# VIP1_top_level register map
Vendor: Texas Instruments
Peripheral module from a debugger description file (folder DRA74xP_75xP_76xP_77xP).
Registers are 32-bit, access per field, reset 0x0 unless marked. A register's access mark holds for its fields unless they carry their own. Offsets are as the file gives them; lines under a group give offsets from that group; [hi:lo] are bit positions; {n}, {i} and the like mark numbered series; 'fields as' and 'values as' point back to an identical list; <NAME> marks a mode.

## VIP1_top_level
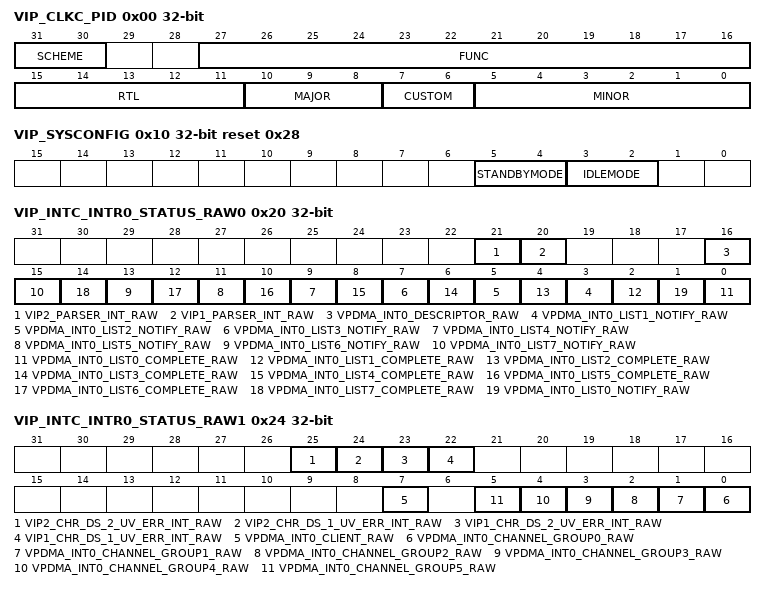
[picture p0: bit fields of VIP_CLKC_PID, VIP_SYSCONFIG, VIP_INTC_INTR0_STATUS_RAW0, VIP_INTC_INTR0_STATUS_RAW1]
0x00 VIP_CLKC_PID ro — This register follows the format described in PDR3.5
  [31:30] SCHEME — The scheme of the register used. This indicates the PDR3.5 Method
  [27:16] FUNC — The function of the module being used
  [15:11] RTL — RTL Release Version The PDR release number of this IP
  [10:8] MAJOR — ajor Release Number
  [7:6] CUSTOM — Custom IP
  [5:0] MINOR — inor Release Number
0x10 VIP_SYSCONFIG reset 0x28
  [5:4] STANDBYMODE rw — Configuration of the local initiator state management mode. By definition, initiator may generate read/write transaction as long as it is out of STANDBY state 0x0: Force-standby mode: local initiator is unconditionally placed in standby state. Backup mode, for debug only 0x1: No-standby mode: local initiator is unconditionally placed out of standby state. Backup mode, for debug only 0x2: Same behavior as bit-field value of 0x1. 0x3: Reserved
  [3:2] IDLEMODE rw — Configuration of the local target state management mode. By definition, target can handle read/write transaction as long as it is out of IDLE state 0x0 : Force-idle mode: local target's idle state follows (acknowledges) the system's idle requests unconditionally, i.e. regardless of the IP module's internal requirements. Backup mode, for debug only 0x1 : No-idle mode: local target never enters idle state. Backup mode, for debug only 0x2 : Smart-idle mode: local target's idle state eventually follows (acknowledges) the system's idle requests, depending on the IP module's internal requirements. IP module shall not generate (IRQ- or DMA-request-related) wakeup events 0x3 : Smart-idle wakeup-capable mode: local target's idle state eventually follows (acknowledges) the system's idle requests, depending on the IP module's internal requirements. IP module may generate (IRQ- or DMA-request-related) wakeup events when in idle state. Mode is only relevant if the appropriate IP module 'swakeup' output(s) is (are) implemented
0x20 VIP_INTC_INTR0_STATUS_RAW0 — INTC INTR0 Interrupt Status Raw/Set Register 0. This register contains the raw interrupt status as defined in HL0.8
  [21] VIP2_PARSER_INT_RAW rw — VIP2 Parser Interrupt Status Read indicates raw status 0 = inactive 1 = active Writing 1 will set status Writing 0 has no effect
  [20] VIP1_PARSER_INT_RAW rw — VIP1 Parser Interrupt Status Read indicates raw status 0 = inactive 1 = active Writing 1 will set status Writing 0 has no effect
  [16] VPDMA_INT0_DESCRIPTOR_RAW rw — VPDMA INT0 Descriptor Status Read indicates raw status 0 = inactive 1 = active Writing 1 will set status Writing 0 has no effect
  [2n+1] VPDMA_INT0_LIST{n}_NOTIFY_RAW rw (n=1..7) — VPDMA INT0 List{n} Complete Status Read indicates raw status 0 = inactive 1 = active Writing 1 will set status Writing 0 has no effect
  [2n] VPDMA_INT0_LIST{n}_COMPLETE_RAW rw (n=0..7) — VPDMA INT0 List{n} Complete Status Read indicates raw status 0 = inactive 1 = active Writing 1 will set status Writing 0 has no effect
  [1] VPDMA_INT0_LIST0_NOTIFY_RAW rw — VPDMA INT0 List0 Notify Status Read indicates raw status 0 = inactive 1 = active Writing 1 will set status Writing 0 has no effect
0x24 VIP_INTC_INTR0_STATUS_RAW1 — INTC INTR0 Interrupt Status Raw/Set Register 1. This register contains the raw interrupt status as defined in HL0.8
  [25] VIP2_CHR_DS_2_UV_ERR_INT_RAW rw — VIP2 Chroma Downsampler 2 UV Error Interrupt Status Read indicates raw status 0 = inactive 1 = active Writing 1 will set status Writing 0 has no effect
  [24] VIP2_CHR_DS_1_UV_ERR_INT_RAW rw — VIP2 Chroma Downsampler 1 UV Error Interrupt Status Read indicates raw status 0 = inactive 1 = active Writing 1 will set status Writing 0 has no effect
  [23] VIP1_CHR_DS_2_UV_ERR_INT_RAW rw — VIP1 Chroma Downsampler 2 UV Error Interrupt Status Read indicates raw status 0 = inactive 1 = active Writing 1 will set status Writing 0 has no effect
  [22] VIP1_CHR_DS_1_UV_ERR_INT_RAW rw — VIP1 Chroma Downsampler 1 UV Error Interrupt Status Read indicates raw status 0 = inactive 1 = active Writing 1 will set status Writing 0 has no effect
  [7] VPDMA_INT0_CLIENT_RAW rw — VPDMA INT0 Client Status Read indicates raw status 0 = inactive 1 = active Writing 1 will set status Writing 0 has no effect
  [n] VPDMA_INT0_CHANNEL_GROUP{n}_RAW rw (n=0..5) — VPDMA INT0 Channel Group{n} Status Read indicates raw status 0 = inactive 1 = active Writing 1 will set status Writing 0 has no effect
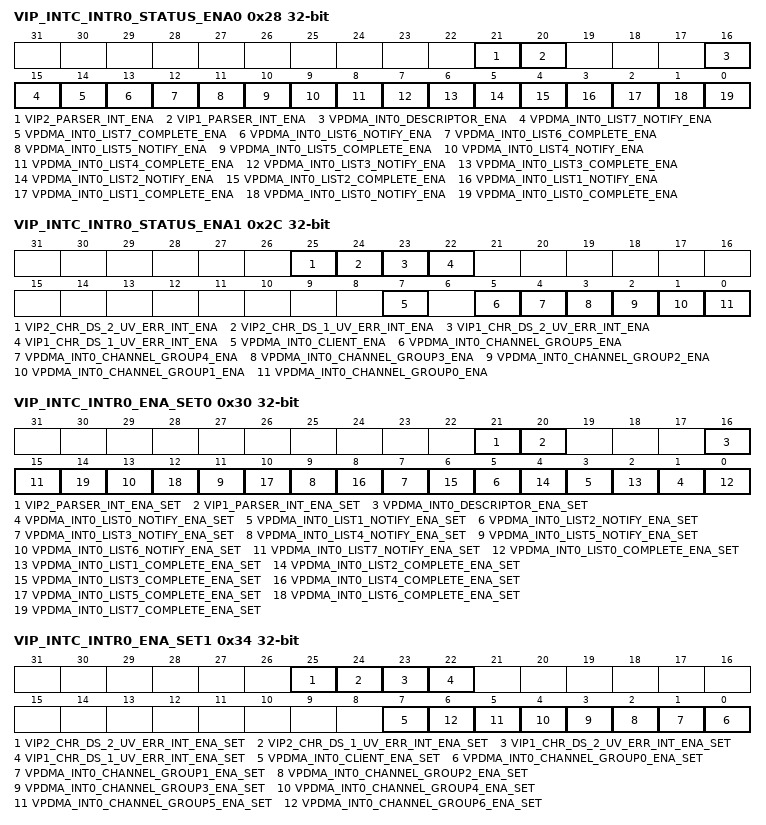
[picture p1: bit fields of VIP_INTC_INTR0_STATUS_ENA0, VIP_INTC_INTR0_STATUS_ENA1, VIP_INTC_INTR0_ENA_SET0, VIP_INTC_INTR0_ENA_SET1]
0x28 VIP_INTC_INTR0_STATUS_ENA0 — INTC INTR0 Interrupt Status Enabled/Clear Register 0. This register contains the enabled interrupt status as defined in HL0.8
  [21] VIP2_PARSER_INT_ENA rw — VIP2 Parser Enabled Interrupt Status Read indicates enabled status 0 = inactive 1 = active Writing 1 will clear interrupt Writing 0 has no effect
  [20] VIP1_PARSER_INT_ENA rw — VIP1 Parser Enabled Interrupt Status Read indicates enabled status 0 = inactive 1 = active Writing 1 will clear interrupt Writing 0 has no effect
  [16] VPDMA_INT0_DESCRIPTOR_ENA rw — VPDMA INT0 Descriptor Enabled Status Read indicates interrupt enable 0 = disabled 1 = enabled Writing 1 will set interrupt enabled Writing 0 has no effect
  [15] VPDMA_INT0_LIST7_NOTIFY_ENA rw — VPDMA INT0 List7 Notify Enabled Status Read indicates interrupt enable 0 = disabled 1 = enabled Writing 1 will set interrupt enabled Writing 0 has no effect
  [14] VPDMA_INT0_LIST7_COMPLETE_ENA rw — VPDMA INT0 List7 Complete Enabled Status Read indicates interrupt enable 0 = disabled 1 = enabled Writing 1 will set interrupt enabled Writing 0 has no effect
  [13] VPDMA_INT0_LIST6_NOTIFY_ENA rw — VPDMA INT0 List6 Notify Enabled Status Read indicates interrupt enable 0 = disabled 1 = enabled Writing 1 will set interrupt enabled Writing 0 has no effect
  [12] VPDMA_INT0_LIST6_COMPLETE_ENA rw — VPDMA INT0 List6 Complete Enabled Status Read indicates interrupt enable 0 = disabled 1 = enabled Writing 1 will set interrupt enabled Writing 0 has no effect
  [11] VPDMA_INT0_LIST5_NOTIFY_ENA rw — VPDMA INT0 List5 Notify Enabled Status Read indicates interrupt enable 0 = disabled 1 = enabled Writing 1 will set interrupt enabled Writing 0 has no effect
  [10] VPDMA_INT0_LIST5_COMPLETE_ENA rw — VPDMA INT0 List5 Complete Enabled Statust Read indicates interrupt enable 0 = disabled 1 = enabled Writing 1 will set interrupt enabled Writing 0 has no effect
  [9] VPDMA_INT0_LIST4_NOTIFY_ENA rw — VPDMA INT0 List4 Notify Enabled Statust Read indicates interrupt enable 0 = disabled 1 = enabled Writing 1 will set interrupt enabled Writing 0 has no effect
  [8] VPDMA_INT0_LIST4_COMPLETE_ENA rw — VPDMA INT0 List4 Complete Enabled Status Read indicates interrupt enable 0 = disabled 1 = enabled Writing 1 will set interrupt enabled Writing 0 has no effect
  [7] VPDMA_INT0_LIST3_NOTIFY_ENA rw — VPDMA INT0 List3 Notify Enabled Status Read indicates interrupt enable 0 = disabled 1 = enabled Writing 1 will set interrupt enabled Writing 0 has no effect
  [6] VPDMA_INT0_LIST3_COMPLETE_ENA rw — VPDMA INT0 List3 Complete Enabled Status Read indicates interrupt enable 0 = disabled 1 = enabled Writing 1 will set interrupt enabled Writing 0 has no effect
  [5] VPDMA_INT0_LIST2_NOTIFY_ENA rw — VPDMA INT0 List2 Notify Enabled Statust Read indicates interrupt enable 0 = disabled 1 = enabled Writing 1 will set interrupt enabled Writing 0 has no effect
  [4] VPDMA_INT0_LIST2_COMPLETE_ENA rw — VPDMA INT0 List2 Complete Enabled Statust Read indicates interrupt enable 0 = disabled 1 = enabled Writing 1 will set interrupt enabled Writing 0 has no effect
  [3] VPDMA_INT0_LIST1_NOTIFY_ENA rw — VPDMA INT0 List1 Notify Enabled Status Read indicates interrupt enable 0 = disabled 1 = enabled Writing 1 will set interrupt enabled Writing 0 has no effect
  [2] VPDMA_INT0_LIST1_COMPLETE_ENA rw — VPDMA INT0 List1 Complete Enabled Status Read indicates interrupt enable 0 = disabled 1 = enabled Writing 1 will set interrupt enabled Writing 0 has no effect
  [1] VPDMA_INT0_LIST0_NOTIFY_ENA rw — VPDMA INT0 List0 Notify Enabled Status Read indicates interrupt enable 0 = disabled 1 = enabled Writing 1 will set interrupt enabled Writing 0 has no effect
  [0] VPDMA_INT0_LIST0_COMPLETE_ENA rw — VPDMA INT0 List0 Complete Enabled Status Read indicates interrupt enable 0 = disabled 1 = enabled Writing 1 will set interrupt enabled Writing 0 has no effect
0x2C VIP_INTC_INTR0_STATUS_ENA1 — INTC INTR0 Interrupt Status Enabled/Clear Register 1. This register contains the enabled interrupt status as defined in HL0.8
  [25] VIP2_CHR_DS_2_UV_ERR_INT_ENA rw — VIP2 Chroma Downsampler 2 UV Error Enabled Interrupt Status Read indicates enabled status 0 = inactive 1 = active Writing 1 will clear interrupt Writing 0 has no effect
  [24] VIP2_CHR_DS_1_UV_ERR_INT_ENA rw — VIP2 Chroma Downsampler 1 UV Error Enabled Interrupt Status Read indicates enabled status 0 = inactive 1 = active Writing 1 will clear interrupt Writing 0 has no effect
  [23] VIP1_CHR_DS_2_UV_ERR_INT_ENA rw — VIP1 Chroma Downsampler 2 UV Error Enabled Interrupt Status Read indicates enabled status 0 = inactive 1 = active Writing 1 will clear interrupt Writing 0 has no effect
  [22] VIP1_CHR_DS_1_UV_ERR_INT_ENA rw — VIP1 Chroma Downsampler 1 UV Error Enabled Interrupt Status Read indicates enabled status 0 = inactive 1 = active Writing 1 will clear interrupt Writing 0 has no effect
  [7] VPDMA_INT0_CLIENT_ENA rw — VPDMA INT0 Client Enabled Status Read indicates raw status 0 = inactive 1 = active Writing 1 will set status Writing 0 has no effect
  [5] VPDMA_INT0_CHANNEL_GROUP5_ENA rw — VPDMA INT0 Channel Group5 Enabled Status Read indicates raw status 0 = inactive 1 = active Writing 1 will set status Writing 0 has no effect
  [4] VPDMA_INT0_CHANNEL_GROUP4_ENA rw — VPDMA INT0 Channel Group4 Enabled Status Read indicates raw status 0 = inactive 1 = active Writing 1 will set status Writing 0 has no effect
  [3] VPDMA_INT0_CHANNEL_GROUP3_ENA rw — VPDMA INT0 Channel Group3 Enabled Status Read indicates raw status 0 = inactive 1 = active Writing 1 will set status Writing 0 has no effect
  [2] VPDMA_INT0_CHANNEL_GROUP2_ENA rw — VPDMA INT0 Channel Group3 Enabled Status Read indicates raw status 0 = inactive 1 = active Writing 1 will set status Writing 0 has no effect
  [1] VPDMA_INT0_CHANNEL_GROUP1_ENA rw — VPDMA INT0 Channel Group1 Enabled Status Read indicates raw status 0 = inactive 1 = active Writing 1 will set status Writing 0 has no effect
  [0] VPDMA_INT0_CHANNEL_GROUP0_ENA rw — VPDMA INT0 Channel Group0 Enabled Status Read indicates raw status 0 = inactive 1 = active Writing 1 will set status Writing 0 has no effect
0x30 VIP_INTC_INTR0_ENA_SET0 — INTC INTR0 Interrupt Enable/Set Register 0. This register contains the interrupt enable status/set as defined in HL0.8
  [21] VIP2_PARSER_INT_ENA_SET rw — VIP2 Parser Enable/Set Read indicates interrupt enable 0 = disabled 1 = enabled Writing 1 will set interrupt enabled Writing 0 has no effect
  [20] VIP1_PARSER_INT_ENA_SET rw — VIP1 Parser Enable/Set Read indicates interrupt enable 0 = disabled 1 = enabled Writing 1 will set interrupt enabled Writing 0 has no effect
  [16] VPDMA_INT0_DESCRIPTOR_ENA_SET rw — VPDMA INT0 Descriptor Enable/Set Read indicates interrupt enable 0 = disabled 1 = enabled Writing 1 will set interrupt enabled Writing 0 has no effect
  [2n+1] VPDMA_INT0_LIST{n}_NOTIFY_ENA_SET rw (n=0..7) — VPDMA INT0 List{n} Notify Enable/Set Read indicates interrupt enable 0 = disabled 1 = enabled Writing 1 will set interrupt enabled Writing 0 has no effect
  [2n] VPDMA_INT0_LIST{n}_COMPLETE_ENA_SET rw (n=0..7) — VPDMA INT0 List{n} Complete Enable/Set Read indicates interrupt enable 0 = disabled 1 = enabled Writing 1 will set interrupt enabled Writing 0 has no effect
0x34 VIP_INTC_INTR0_ENA_SET1 — INTC INTR0 Interrupt Enable/Set Register 1. This register contains the interrupt enable status/set as defined in HL0.8
  [25] VIP2_CHR_DS_2_UV_ERR_INT_ENA_SET rw — VIP2 Chroma Downsampler 2 UV Error Enable/Set Read indicates interrupt enable 0 = disabled 1 = enabled Writing 1 will set interrupt enabled Writing 0 has no effect
  [24] VIP2_CHR_DS_1_UV_ERR_INT_ENA_SET rw — VIP2 Chroma Downsampler 1 UV Error Enable/Set Read indicates interrupt enable 0 = disabled 1 = enabled Writing 1 will set interrupt enabled Writing 0 has no effect
  [23] VIP1_CHR_DS_2_UV_ERR_INT_ENA_SET rw — VIP1 Chroma Downsampler 2 UV Error Enable/Set Read indicates interrupt enable 0 = disabled 1 = enabled Writing 1 will set interrupt enabled Writing 0 has no effect
  [22] VIP1_CHR_DS_1_UV_ERR_INT_ENA_SET rw — VIP1 Chroma Downsampler 1 UV Error Enable/Set Read indicates interrupt enable 0 = disabled 1 = enabled Writing 1 will set interrupt enabled Writing 0 has no effect
  [7] VPDMA_INT0_CLIENT_ENA_SET rw — VPDMA INT0 Client Enable/Set Read indicates interrupt enable 0 = disabled 1 = enabled Writing 1 will set interrupt enabled Writing 0 has no effect
  [n] VPDMA_INT0_CHANNEL_GROUP{n}_ENA_SET rw (n=0..6) — VPDMA INT0 Channel Group{n} Enable/Set Read indicates interrupt enable 0 = disabled 1 = enabled Writing 1 will set interrupt enabled Writing 0 has no effect
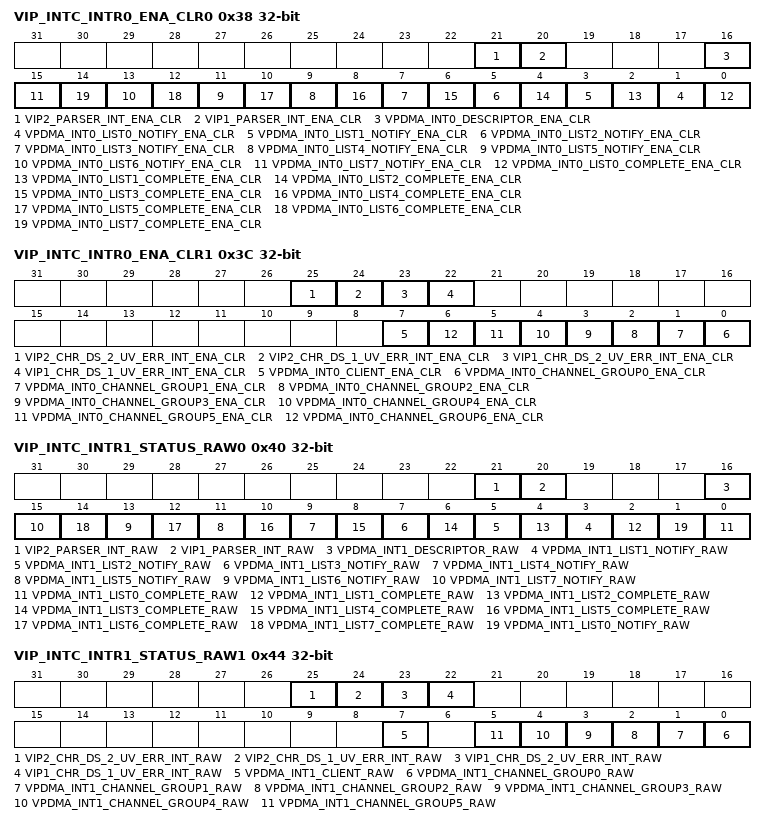
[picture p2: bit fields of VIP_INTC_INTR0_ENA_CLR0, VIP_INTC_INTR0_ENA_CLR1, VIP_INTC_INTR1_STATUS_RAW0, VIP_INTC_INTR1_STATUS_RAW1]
0x38 VIP_INTC_INTR0_ENA_CLR0 — INTC INTR0 Interrupt Enable/Clear Register 0. This register contains the interrupt enable status/clear as defined in HL0.8
  [21] VIP2_PARSER_INT_ENA_CLR rw — VIP2 Parser Enable/Clear Read indicates interrupt enable 0 = disabled 1 = enabled Writing 1 will clear interrupt enabled Writing 0 has no effect
  [20] VIP1_PARSER_INT_ENA_CLR rw — VIP1 Parser Enable/Clear Read indicates interrupt enable 0 = disabled 1 = enabled Writing 1 will clear interrupt enabled Writing 0 has no effect
  [16] VPDMA_INT0_DESCRIPTOR_ENA_CLR rw — VPDMA INT0 Descriptor Enable/Clear Read indicates interrupt enable 0 = disabled 1 = enabled Writing 1 will clear interrupt enabled Writing 0 has no effect
  [2n+1] VPDMA_INT0_LIST{n}_NOTIFY_ENA_CLR rw (n=0..7) — VPDMA INT0 List{n} Notify Enable/Clear Read indicates interrupt enable 0 = disabled 1 = enabled Writing 1 will clear interrupt enabled Writing 0 has no effect
  [2n] VPDMA_INT0_LIST{n}_COMPLETE_ENA_CLR rw (n=0..7) — VPDMA INT0 List{n} Complete Enable/Clear Read indicates interrupt enable 0 = disabled 1 = enabled Writing 1 will clear interrupt enabled Writing 0 has no effect
0x3C VIP_INTC_INTR0_ENA_CLR1 — INTC INTR0 Interrupt Enable/Clear Register 1. This register contains the interrupt enable status/clear as defined in HL0.8
  [25] VIP2_CHR_DS_2_UV_ERR_INT_ENA_CLR rw — VIP2 Chroma Downsampler 2 UV Error Enable/Clear Read indicates interrupt enable 0 = disabled 1 = enabled Writing 1 will clear interrupt enabled Writing 0 has no effect
  [24] VIP2_CHR_DS_1_UV_ERR_INT_ENA_CLR rw — VIP2 Chroma Downsampler 1 UV Error Enable/Clear Read indicates interrupt enable 0 = disabled 1 = enabled Writing 1 will clear interrupt enabled Writing 0 has no effect
  [23] VIP1_CHR_DS_2_UV_ERR_INT_ENA_CLR rw — VIP1 Chroma Downsampler 2 UV Error Enable/Clear Read indicates interrupt enable 0 = disabled 1 = enabled Writing 1 will clear interrupt enabled Writing 0 has no effect
  [22] VIP1_CHR_DS_1_UV_ERR_INT_ENA_CLR rw — VIP1 Chroma Downsampler 1 UV Error Enable/Clear Read indicates interrupt enable 0 = disabled 1 = enabled Writing 1 will clear interrupt enabled Writing 0 has no effect
  [7] VPDMA_INT0_CLIENT_ENA_CLR rw — VPDMA INT0 Client Enable/Clear Read indicates interrupt enable 0 = disabled 1 = enabled Writing 1 will clear interrupt enabled Writing 0 has no effect
  [n] VPDMA_INT0_CHANNEL_GROUP{n}_ENA_CLR rw (n=0..6) — VPDMA INT0 Channel Group{n} Enable/Clear Read indicates interrupt enable 0 = disabled 1 = enabled Writing 1 will clear interrupt enabled Writing 0 has no effect
0x40 VIP_INTC_INTR1_STATUS_RAW0 — INTC intr1 Interrupt Status Raw/Set Register 0. This register contains the raw interrupt status as defined in HL0.8
  [21] VIP2_PARSER_INT_RAW rw — VIP2 Parser Interrupt Status Read indicates raw status 0 = inactive 1 = active Writing 1 will set status Writing 0 has no effect
  [20] VIP1_PARSER_INT_RAW rw — VIP1 Parser Interrupt Status Read indicates raw status 0 = inactive 1 = active Writing 1 will set status Writing 0 has no effect
  [16] VPDMA_INT1_DESCRIPTOR_RAW rw — VPDMA INT1 Descriptor Status Read indicates raw status 0 = inactive 1 = active Writing 1 will set status Writing 0 has no effect
  [2n+1] VPDMA_INT1_LIST{n}_NOTIFY_RAW rw (n=1..7) — VPDMA INT1 List{n} Complete Status Read indicates raw status 0 = inactive 1 = active Writing 1 will set status Writing 0 has no effect
  [2n] VPDMA_INT1_LIST{n}_COMPLETE_RAW rw (n=0..7) — VPDMA INT1 List{n} Complete Status Read indicates raw status 0 = inactive 1 = active Writing 1 will set status Writing 0 has no effect
  [1] VPDMA_INT1_LIST0_NOTIFY_RAW rw — VPDMA INT1 List0 Notify Status Read indicates raw status 0 = inactive 1 = active Writing 1 will set status Writing 0 has no effect
0x44 VIP_INTC_INTR1_STATUS_RAW1 — INTC intr1 Interrupt Status Raw/Set Register 1. This register contains the raw interrupt status as defined in HL0.8
  [25] VIP2_CHR_DS_2_UV_ERR_INT_RAW rw — VIP2 Chroma Downsampler 2 UV Error Interrupt Status Read indicates raw status 0 = inactive 1 = active Writing 1 will set status Writing 0 has no effect
  [24] VIP2_CHR_DS_1_UV_ERR_INT_RAW rw — VIP2 Chroma Downsampler 1 UV Error Interrupt Status Read indicates raw status 0 = inactive 1 = active Writing 1 will set status Writing 0 has no effect
  [23] VIP1_CHR_DS_2_UV_ERR_INT_RAW rw — VIP1 Chroma Downsampler 2 UV Error Interrupt Status Read indicates raw status 0 = inactive 1 = active Writing 1 will set status Writing 0 has no effect
  [22] VIP1_CHR_DS_1_UV_ERR_INT_RAW rw — VIP1 Chroma Downsampler 1 UV Error Interrupt Status Read indicates raw status 0 = inactive 1 = active Writing 1 will set status Writing 0 has no effect
  [7] VPDMA_INT1_CLIENT_RAW rw — VPDMA INT1 Client Status Read indicates raw status 0 = inactive 1 = active Writing 1 will set status Writing 0 has no effect
  [n] VPDMA_INT1_CHANNEL_GROUP{n}_RAW rw (n=0..5) — VPDMA INT1 Channel Group{n} Status Read indicates raw status 0 = inactive 1 = active Writing 1 will set status Writing 0 has no effect
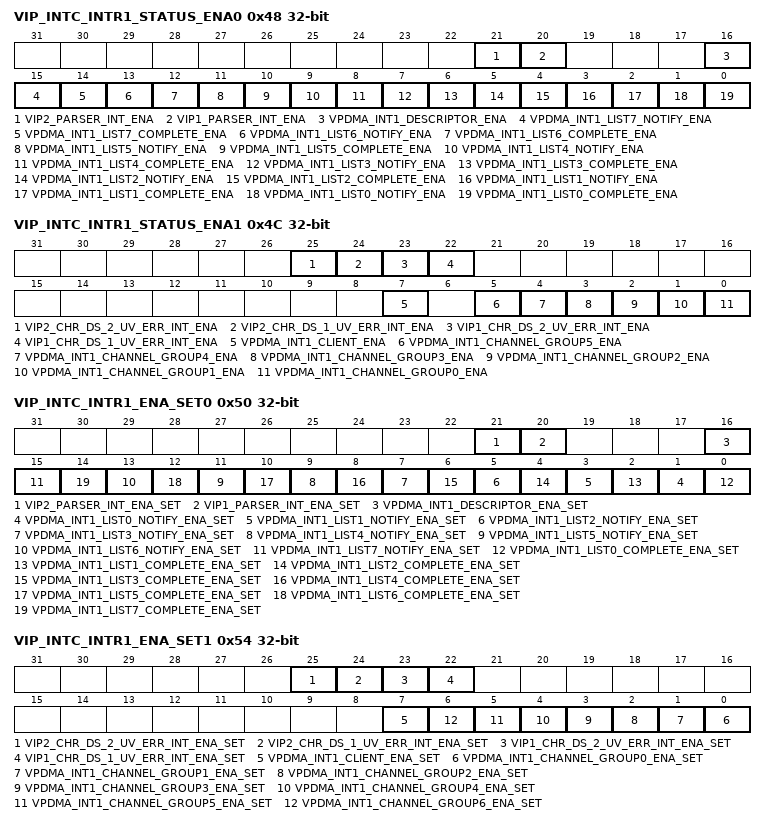
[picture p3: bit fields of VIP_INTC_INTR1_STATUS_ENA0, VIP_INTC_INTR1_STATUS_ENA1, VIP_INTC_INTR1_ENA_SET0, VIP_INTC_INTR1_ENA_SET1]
0x48 VIP_INTC_INTR1_STATUS_ENA0 — INTC intr1 Interrupt Status Enabled/Clear Register 0. This register contains the enabled interrupt status as defined in HL0.8
  [21] VIP2_PARSER_INT_ENA rw — VIP2 Parser Enabled Interrupt Status Read indicates enabled status 0 = inactive 1 = active Writing 1 will clear interrupt Writing 0 has no effect
  [20] VIP1_PARSER_INT_ENA rw — VIP1 Parser Enabled Interrupt Status Read indicates enabled status 0 = inactive 1 = active Writing 1 will clear interrupt Writing 0 has no effect
  [16] VPDMA_INT1_DESCRIPTOR_ENA rw — VPDMA INT1 Descriptor Enabled Status Read indicates interrupt enable 0 = disabled 1 = enabled Writing 1 will set interrupt enabled Writing 0 has no effect
  [15] VPDMA_INT1_LIST7_NOTIFY_ENA rw — VPDMA INT1 List7 Notify Enabled Status Read indicates interrupt enable 0 = disabled 1 = enabled Writing 1 will set interrupt enabled Writing 0 has no effect
  [14] VPDMA_INT1_LIST7_COMPLETE_ENA rw — VPDMA INT1 List7 Complete Enabled Status Read indicates interrupt enable 0 = disabled 1 = enabled Writing 1 will set interrupt enabled Writing 0 has no effect
  [13] VPDMA_INT1_LIST6_NOTIFY_ENA rw — VPDMA INT1 List6 Notify Enabled Status Read indicates interrupt enable 0 = disabled 1 = enabled Writing 1 will set interrupt enabled Writing 0 has no effect
  [12] VPDMA_INT1_LIST6_COMPLETE_ENA rw — VPDMA INT1 List6 Complete Enabled Status Read indicates interrupt enable 0 = disabled 1 = enabled Writing 1 will set interrupt enabled Writing 0 has no effect
  [11] VPDMA_INT1_LIST5_NOTIFY_ENA rw — VPDMA INT1 List5 Notify Enabled Status Read indicates interrupt enable 0 = disabled 1 = enabled Writing 1 will set interrupt enabled Writing 0 has no effect
  [10] VPDMA_INT1_LIST5_COMPLETE_ENA rw — VPDMA INT1 List5 Complete Enabled Statust Read indicates interrupt enable 0 = disabled 1 = enabled Writing 1 will set interrupt enabled Writing 0 has no effect
  [9] VPDMA_INT1_LIST4_NOTIFY_ENA rw — VPDMA INT1 List4 Notify Enabled Statust Read indicates interrupt enable 0 = disabled 1 = enabled Writing 1 will set interrupt enabled Writing 0 has no effect
  [8] VPDMA_INT1_LIST4_COMPLETE_ENA rw — VPDMA INT1 List4 Complete Enabled Status Read indicates interrupt enable 0 = disabled 1 = enabled Writing 1 will set interrupt enabled Writing 0 has no effect
  [7] VPDMA_INT1_LIST3_NOTIFY_ENA rw — VPDMA INT1 List3 Notify Enabled Status Read indicates interrupt enable 0 = disabled 1 = enabled Writing 1 will set interrupt enabled Writing 0 has no effect
  [6] VPDMA_INT1_LIST3_COMPLETE_ENA rw — VPDMA INT1 List3 Complete Enabled Status Read indicates interrupt enable 0 = disabled 1 = enabled Writing 1 will set interrupt enabled Writing 0 has no effect
  [5] VPDMA_INT1_LIST2_NOTIFY_ENA rw — VPDMA INT1 List2 Notify Enabled Statust Read indicates interrupt enable 0 = disabled 1 = enabled Writing 1 will set interrupt enabled Writing 0 has no effect
  [4] VPDMA_INT1_LIST2_COMPLETE_ENA rw — VPDMA INT1 List2 Complete Enabled Statust Read indicates interrupt enable 0 = disabled 1 = enabled Writing 1 will set interrupt enabled Writing 0 has no effect
  [3] VPDMA_INT1_LIST1_NOTIFY_ENA rw — VPDMA INT1 List1 Notify Enabled Status Read indicates interrupt enable 0 = disabled 1 = enabled Writing 1 will set interrupt enabled Writing 0 has no effect
  [2] VPDMA_INT1_LIST1_COMPLETE_ENA rw — VPDMA INT1 List1 Complete Enabled Status Read indicates interrupt enable 0 = disabled 1 = enabled Writing 1 will set interrupt enabled Writing 0 has no effect
  [1] VPDMA_INT1_LIST0_NOTIFY_ENA rw — VPDMA INT1 List0 Notify Enabled Status Read indicates interrupt enable 0 = disabled 1 = enabled Writing 1 will set interrupt enabled Writing 0 has no effect
  [0] VPDMA_INT1_LIST0_COMPLETE_ENA rw — VPDMA INT1 List0 Complete Enabled Status Read indicates interrupt enable 0 = disabled 1 = enabled Writing 1 will set interrupt enabled Writing 0 has no effect
0x4C VIP_INTC_INTR1_STATUS_ENA1 — INTC intr1 Interrupt Status Enabled/Clear Register 1. This register contains the enabled interrupt status as defined in HL0.8
  [25] VIP2_CHR_DS_2_UV_ERR_INT_ENA rw — VIP2 Chroma Downsampler 2 UV Error Enabled Interrupt Status Read indicates enabled status 0 = inactive 1 = active Writing 1 will clear interrupt Writing 0 has no effect
  [24] VIP2_CHR_DS_1_UV_ERR_INT_ENA rw — VIP2 Chroma Downsampler 1 UV Error Enabled Interrupt Status Read indicates enabled status 0 = inactive 1 = active Writing 1 will clear interrupt Writing 0 has no effect
  [23] VIP1_CHR_DS_2_UV_ERR_INT_ENA rw — VIP1 Chroma Downsampler 2 UV Error Enabled Interrupt Status Read indicates enabled status 0 = inactive 1 = active Writing 1 will clear interrupt Writing 0 has no effect
  [22] VIP1_CHR_DS_1_UV_ERR_INT_ENA rw — VIP1 Chroma Downsampler 1 UV Error Enabled Interrupt Status Read indicates enabled status 0 = inactive 1 = active Writing 1 will clear interrupt Writing 0 has no effect
  [7] VPDMA_INT1_CLIENT_ENA rw — VPDMA INT1 Client Enabled Status Read indicates raw status 0 = inactive 1 = active Writing 1 will set status Writing 0 has no effect
  [5] VPDMA_INT1_CHANNEL_GROUP5_ENA rw — VPDMA INT1 Channel Group5 Enabled Status Read indicates raw status 0 = inactive 1 = active Writing 1 will set status Writing 0 has no effect
  [4] VPDMA_INT1_CHANNEL_GROUP4_ENA rw — VPDMA INT1 Channel Group4 Enabled Status Read indicates raw status 0 = inactive 1 = active Writing 1 will set status Writing 0 has no effect
  [3] VPDMA_INT1_CHANNEL_GROUP3_ENA rw — VPDMA INT1 Channel Group3 Enabled Status Read indicates raw status 0 = inactive 1 = active Writing 1 will set status Writing 0 has no effect
  [2] VPDMA_INT1_CHANNEL_GROUP2_ENA rw — VPDMA INT1 Channel Group3 Enabled Status Read indicates raw status 0 = inactive 1 = active Writing 1 will set status Writing 0 has no effect
  [1] VPDMA_INT1_CHANNEL_GROUP1_ENA rw — VPDMA INT1 Channel Group1 Enabled Status Read indicates raw status 0 = inactive 1 = active Writing 1 will set status Writing 0 has no effect
  [0] VPDMA_INT1_CHANNEL_GROUP0_ENA rw — VPDMA INT1 Channel Group0 Enabled Status Read indicates raw status 0 = inactive 1 = active Writing 1 will set status Writing 0 has no effect
0x50 VIP_INTC_INTR1_ENA_SET0 — INTC intr1 Interrupt Enable/Set Register 0. This register contains the interrupt enable status/set as defined in HL0.8
  [21] VIP2_PARSER_INT_ENA_SET rw — VIP2 Parser Enable/Set Read indicates interrupt enable 0 = disabled 1 = enabled Writing 1 will set interrupt enabled Writing 0 has no effect
  [20] VIP1_PARSER_INT_ENA_SET rw — VIP1 Parser Enable/Set Read indicates interrupt enable 0 = disabled 1 = enabled Writing 1 will set interrupt enabled Writing 0 has no effect
  [16] VPDMA_INT1_DESCRIPTOR_ENA_SET rw — VPDMA INT1 Descriptor Enable/Set Read indicates interrupt enable 0 = disabled 1 = enabled Writing 1 will set interrupt enabled Writing 0 has no effect
  [2n+1] VPDMA_INT1_LIST{n}_NOTIFY_ENA_SET rw (n=0..7) — VPDMA INT1 List{n} Notify Enable/Set Read indicates interrupt enable 0 = disabled 1 = enabled Writing 1 will set interrupt enabled Writing 0 has no effect
  [2n] VPDMA_INT1_LIST{n}_COMPLETE_ENA_SET rw (n=0..7) — VPDMA INT1 List{n} Complete Enable/Set Read indicates interrupt enable 0 = disabled 1 = enabled Writing 1 will set interrupt enabled Writing 0 has no effect
0x54 VIP_INTC_INTR1_ENA_SET1 — INTC intr1 Interrupt Enable/Set Register 1. This register contains the interrupt enable status/set as defined in HL0.8
  [25] VIP2_CHR_DS_2_UV_ERR_INT_ENA_SET rw — VIP2 Chroma Downsampler 2 UV Error Enable/Set Read indicates interrupt enable 0 = disabled 1 = enabled Writing 1 will set interrupt enabled Writing 0 has no effect
  [24] VIP2_CHR_DS_1_UV_ERR_INT_ENA_SET rw — VIP2 Chroma Downsampler 1 UV Error Enable/Set Read indicates interrupt enable 0 = disabled 1 = enabled Writing 1 will set interrupt enabled Writing 0 has no effect
  [23] VIP1_CHR_DS_2_UV_ERR_INT_ENA_SET rw — VIP1 Chroma Downsampler 2 UV Error Enable/Set Read indicates interrupt enable 0 = disabled 1 = enabled Writing 1 will set interrupt enabled Writing 0 has no effect
  [22] VIP1_CHR_DS_1_UV_ERR_INT_ENA_SET rw — VIP1 Chroma Downsampler 1 UV Error Enable/Set Read indicates interrupt enable 0 = disabled 1 = enabled Writing 1 will set interrupt enabled Writing 0 has no effect
  [7] VPDMA_INT1_CLIENT_ENA_SET rw — VPDMA INT1 Client Enable/Set Read indicates interrupt enable 0 = disabled 1 = enabled Writing 1 will set interrupt enabled Writing 0 has no effect
  [n] VPDMA_INT1_CHANNEL_GROUP{n}_ENA_SET rw (n=0..6) — VPDMA INT1 Channel Group{n} Enable/Set Read indicates interrupt enable 0 = disabled 1 = enabled Writing 1 will set interrupt enabled Writing 0 has no effect
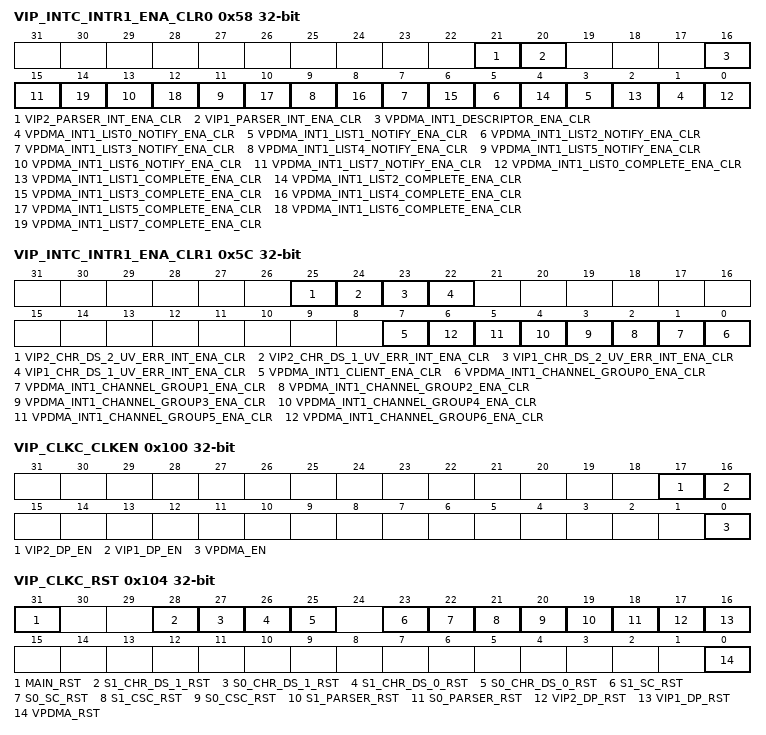
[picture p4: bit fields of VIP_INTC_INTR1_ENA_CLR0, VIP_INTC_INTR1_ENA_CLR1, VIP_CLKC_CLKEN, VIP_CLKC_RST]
0x58 VIP_INTC_INTR1_ENA_CLR0 — INTC intr1 Interrupt Enable/Clear Register 0. This register contains the interrupt enable status/clear as defined in HL0.8
  [21] VIP2_PARSER_INT_ENA_CLR rw — VIP2 Parser Enable/Clear Read indicates interrupt enable 0 = disabled 1 = enabled Writing 1 will clear interrupt enabled Writing 0 has no effect
  [20] VIP1_PARSER_INT_ENA_CLR rw — VIP1 Parser Enable/Clear Read indicates interrupt enable 0 = disabled 1 = enabled Writing 1 will clear interrupt enabled Writing 0 has no effect
  [16] VPDMA_INT1_DESCRIPTOR_ENA_CLR rw — VPDMA INT1 Descriptor Enable/Clear Read indicates interrupt enable 0 = disabled 1 = enabled Writing 1 will clear interrupt enabled Writing 0 has no effect
  [2n+1] VPDMA_INT1_LIST{n}_NOTIFY_ENA_CLR rw (n=0..7) — VPDMA INT1 List{n} Notify Enable/Clear Read indicates interrupt enable 0 = disabled 1 = enabled Writing 1 will clear interrupt enabled Writing 0 has no effect
  [2n] VPDMA_INT1_LIST{n}_COMPLETE_ENA_CLR rw (n=0..7) — VPDMA INT1 List{n} Complete Enable/Clear Read indicates interrupt enable 0 = disabled 1 = enabled Writing 1 will clear interrupt enabled Writing 0 has no effect
0x5C VIP_INTC_INTR1_ENA_CLR1 — INTC intr1 Interrupt Enable/Clear Register 1. This register contains the interrupt enable status/clear as defined in HL0.8
  [25] VIP2_CHR_DS_2_UV_ERR_INT_ENA_CLR rw — VIP2 Chroma Downsampler 2 UV Error Enable/Clear Read indicates interrupt enable 0 = disabled 1 = enabled Writing 1 will clear interrupt enabled Writing 0 has no effect
  [24] VIP2_CHR_DS_1_UV_ERR_INT_ENA_CLR rw — VIP2 Chroma Downsampler 1 UV Error Enable/Clear Read indicates interrupt enable 0 = disabled 1 = enabled Writing 1 will clear interrupt enabled Writing 0 has no effect
  [23] VIP1_CHR_DS_2_UV_ERR_INT_ENA_CLR rw — VIP1 Chroma Downsampler 2 UV Error Enable/Clear Read indicates interrupt enable 0 = disabled 1 = enabled Writing 1 will clear interrupt enabled Writing 0 has no effect
  [22] VIP1_CHR_DS_1_UV_ERR_INT_ENA_CLR rw — VIP1 Chroma Downsampler 1 UV Error Enable/Clear Read indicates interrupt enable 0 = disabled 1 = enabled Writing 1 will clear interrupt enabled Writing 0 has no effect
  [7] VPDMA_INT1_CLIENT_ENA_CLR rw — VPDMA INT1 Client Enable/Clear Read indicates interrupt enable 0 = disabled 1 = enabled Writing 1 will clear interrupt enabled Writing 0 has no effect
  [n] VPDMA_INT1_CHANNEL_GROUP{n}_ENA_CLR rw (n=0..6) — VPDMA INT1 Channel Group{n} Enable/Clear Read indicates interrupt enable 0 = disabled 1 = enabled Writing 1 will clear interrupt enabled Writing 0 has no effect
0xA0 VIP_INTC_EOI rw — INTC EOI Register. This register contains the EOI vector register contents as defined by HL0.8
  [31:0] EOI_VECTOR — Number associated with the ipgenericirq for intr output. There are 4 interrupt outputs Write 0x0 : Write to intr0 IP Generic Write 0x1 : Write to intr1 IP Generic Write 0x2 : Write to intr2 IP Generic Write 0x3 : Write to intr3 IP Generic Any other write value is ignored.
0x100 VIP_CLKC_CLKEN — CLKC Module Clock Enable Register. This register contains clock enables for the processing paths in the VIP module.Added missing bit-fields to VIP_CLKC_CLKEN and VIP_CLKC_RST registers. See Appendix B for more details
  [17] VIP2_DP_EN rw — VIP Slice1 Data Path Clock Enable, 1 = Clock Enabled, 0 = Clock Disabled
  [16] VIP1_DP_EN rw — VIP Slice0 Data Path Clock Enable, 1 = Clock Enabled, 0 = Clock Disabled
  [0] VPDMA_EN rw — VPDMA Clock Enable, 1 = Clock Enabled, 0 = Clock Disabled
0x104 VIP_CLKC_RST — CLKC Module Reset Register. This register contains resets for the processing paths in the VIP module.
  [31] MAIN_RST rw — Reset for all modules in VIP Main Data Path
  [28] S1_CHR_DS_1_RST rw — VIP Slice1 CHRDS1 reset
  [27] S0_CHR_DS_1_RST rw — VIP Slice0 CHRDS1 reset
  [26] S1_CHR_DS_0_RST rw — VIP Slice1 CHRDS0 reset
  [25] S0_CHR_DS_0_RST rw — VIP Slice0 CHRDS0 reset
  [23] S1_SC_RST rw — VIP Slice1 SC reset
  [22] S0_SC_RST rw — VIP Slice0 SC reset
  [21] S1_CSC_RST rw — VIP Slice1 CSC reset
  [20] S0_CSC_RST rw — VIP Slice0 CSC reset
  [19] S1_PARSER_RST rw — VIP Slice1 parser reset
  [18] S0_PARSER_RST rw — VIP Slice0 parser reset
  [17] VIP2_DP_RST rw — VIP Slice1 Data Path Reset
  [16] VIP1_DP_RST rw — VIP Slice0 Data Path Reset
  [0] VPDMA_RST rw — VPDMA Reset
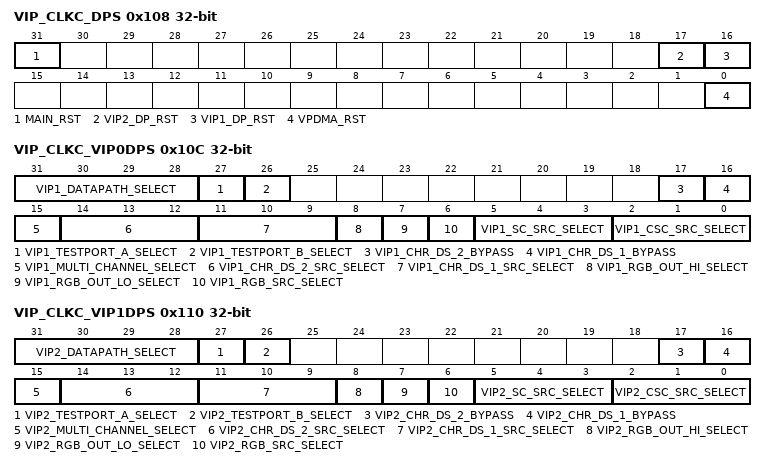
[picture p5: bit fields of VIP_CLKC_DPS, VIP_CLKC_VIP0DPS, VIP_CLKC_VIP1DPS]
0x108 VIP_CLKC_DPS — CLKC Main Data Path Select Register. This register selects the various data paths within main portion (non-VIP) of the subsystem
  [31] MAIN_RST rw — Reset for all modules in DSS Main Data Path
  [17] VIP2_DP_RST rw — Video Input Port 2 Data Path Reset
  [16] VIP1_DP_RST rw — Video Input Port 1 Data Path Reset
  [0] VPDMA_RST rw — VPDMA Reset
0x10C VIP_CLKC_VIP0DPS — CLKC Video Input Port 1 Data Path Select Register. This register selects the various data paths within the Video Input Port portion of the subsystem
  [31:28] VIP1_DATAPATH_SELECT rw — VIP1 Datapath Register Field Enable 0000 : All fields written 0001 : Only vip1_csc_src_select written 0010 : Only vip1_sc_src_select written 0011 : Only vip1_rgb_src_select written 0100 : Only vip1_rgb_out_lo_select written 0101 : Only vip1_rgb_out_hi_select written 0110 : Only vip1_chr_ds_1_src_select written 0111 : Only vip1_chr_ds_2_src_select written 1000 : Only vip1_multi_channel_select written 1001 : Only vip1_chr_ds_1_bypass written 1010 : Only vip1_chr_ds_2_bypass written 1011 : Reserved 1100 : Reserved 1101 : Reserved 1110 : Reserved 1111 : Reserved
  [27] VIP1_TESTPORT_A_SELECT rw — 0 : Normal mode 1: Test Mode
  [26] VIP1_TESTPORT_B_SELECT rw — 0 : Normal mode 1: Test Mode
  [17] VIP1_CHR_DS_2_BYPASS rw — Video Input Port 1 Chroma Downsampler 2 Bypass 0 : VIP Chroma Downsampler 1 selected 1 : VIP Chroma Downsampler 1 Bypassed Chroma Downsampler Bypassed means the output format from the VIP will be 422 data. Selected means the output format will be 420
  [16] VIP1_CHR_DS_1_BYPASS rw — Video Input Port 1 Chroma Downsampler 1 Bypass 0 : VIP Chroma Downsampler 1 selected 1 : VIP Chroma Downsampler 1 Bypassed Chroma Downsampler Bypassed means the output format from the VIP will be 422 data. Selected means the output format will be 420
  [15] VIP1_MULTI_CHANNEL_SELECT rw — Video Input Port 1 Multi Channel Select 0 : VIP_PARSER A and B channels operate in single channel mode 1 : VIP_PARSER A and B channels directly drive VPDMA (multi-channel case) Multi-Channel means that the A and B sources are from multiple channels and used in a multiplexed stream mode. The VIP Parser extracts the channel ID from each source and outputs this information to VPDMA, and thus to memory. When operating in a multiplexed stream mode, this bit must be set to 1 to enable the channel information to be passed to memory. If this is not set, the channel number (or source number) will be 0 for all streams. If vip1_rgb_out_select = 1, then VIP_PARSER A port is connected to VPDMA
  [14:12] VIP1_CHR_DS_2_SRC_SELECT rw — Video Input Port 1 Chroma Downsampler 2 Source Select 0 : Path Disabled (no input to CHR_DS) 1 : Source from Scaler (SC_M) 2 : Source from Color Space Converter (CSC) 3 : Source from VIP_PARSER A port 4 : Source from VIP_PARSER B port 5 : Source from Transcode (422) 6 : Reserved 7 : Reserved
  [11:9] VIP1_CHR_DS_1_SRC_SELECT rw — Video Input Port 1 Chroma Downsampler 1 Source Select 000 : Path Disabled (no input to CHR_DS) 001 : Source from Scaler (SC_M) 010 : Source from Color Space Converter (CSC) 011 : Source from VIP_PARSER A port 100 : Source from VIP_PARSER B port 101 : Source from Transcode (422) 110 : Reserved 111 : Reserved
  [8] VIP1_RGB_OUT_HI_SELECT rw — Video Input Port 1 HI RGB Output Select 0 : Output Type is 420/422 1 : Output Type is RGB
  [7] VIP1_RGB_OUT_LO_SELECT rw — Video Input Port 1 LO RGB Output Select 0 : Output Type is 420/422 1 : Output Type is RGB
  [6] VIP1_RGB_SRC_SELECT rw — Video Input Port 1 RGB Output Path Select 0 : Source from Compositor RGB input 1 : Source from CSC
  [5:3] VIP1_SC_SRC_SELECT rw — Video Input Port 1 SC_M Source Select 000 : Path Disabled 001 : Source from Color Space Converter (CSC) 010 : Source from VIP_PARSER A port 011 : Source from VIP_PARSER B port 100 : Source from Transcode (422) 101 : Reserved 110 : Reserved 111 : Reserved
  [2:0] VIP1_CSC_SRC_SELECT rw — Video Input Port 1 CSC Source Select 000 : Path Disabled 001 : Source from VIP_PARSER A (422) port 010 : Source from VIP_PARSER B port 011 : Source from Transcode (422) 100 : Source from VIP_PARSER A (RGB) port 101 : Source from Compositor (RGB) 110 : Reserved 111 : Reserved
0x110 VIP_CLKC_VIP1DPS — CLKC Video Input Port 2 Data Path Select Register. This register selects the various data paths within the Video Input Port portion of the subsystem
  [31:28] VIP2_DATAPATH_SELECT rw — VIP2 Datapath Register Field Enable 0000 : All fields written 0001 : Only vip2_csc_src_select written 0010 : Only vip2_sc_src_select written 0011 : Only vip2_rgb_src_select written 0100 : Only vip2_rgb_out_lo_select written 0101 : Only vip2_rgb_out_hi_select written 0110 : Only vip2_chr_ds_1_src_select written 0111 : Only vip2_chr_ds_2_src_select written 1000 : Only vip2_multi_channel_select written 1001 : Only vip2_chr_ds_1_bypass written 1010 : Only vip2_chr_ds_2_bypass written 1011 : Reserved 1100 : Reserved 1101 : Reserved 1110 : Reserved 1111 : Reserved
  [27] VIP2_TESTPORT_A_SELECT rw — 0 : Normal mode 1: Test Mode
  [26] VIP2_TESTPORT_B_SELECT rw — 0 : Normal mode 1: Test Mode
  [17] VIP2_CHR_DS_2_BYPASS rw — Video Input Port 2 Chroma Downsampler 2 Bypass 0 : VIP Chroma Downsampler 1 selected 1 : VIP Chroma Downsampler 1 Bypassed Chroma Downsampler Bypassed means the output format from the VIP will be 422 data. Selected means the output format will be 420
  [16] VIP2_CHR_DS_1_BYPASS rw — Video Input Port 2 Chroma Downsampler 1 Bypass 0 : VIP Chroma Downsampler 1 selected 1 : VIP Chroma Downsampler 1 Bypassed Chroma Downsampler Bypassed means the output format from the VIP will be 422 data. Selected means the output format will be 420
  [15] VIP2_MULTI_CHANNEL_SELECT rw — Video Input Port 2 Multi Channel Select 0 : VIP_PARSER A and B channels operate in single channel mode 1 : VIP_PARSER A and B channels directly drive VPDMA (multi-channel case) Multi-Channel means that the A and B sources are from multiple channels and used in a multiplexed stream mode. The VIP Parser extracts the channel ID from each source and outputs this information to VPDMA, and thus to memory. When operating in a multiplexed stream mode, this bit must be set to 1 to enable the channel information to be passed to memory. If this is not set, the channel number (or source number) will be 0 for all streams. If vip2_rgb_out_select = 1, then VIP_PARSER A port is connected to VPDMA
  [14:12] VIP2_CHR_DS_2_SRC_SELECT rw — Video Input Port 2 Chroma Downsampler 2 Source Select 0 : Path Disabled (no input to CHR_DS) 1 : Source from Scaler (SC_M) 2 : Source from Color Space Converter (CSC) 3 : Source from VIP_PARSER A port 4 : Source from VIP_PARSER B port 5 : Source from Transcode (422) 6 : Reserved 7 : Reserved
  [11:9] VIP2_CHR_DS_1_SRC_SELECT rw — Video Input Port 2 Chroma Downsampler 1 Source Select 000 : Path Disabled (no input to CHR_DS) 001 : Source from Scaler (SC_M) 010 : Source from Color Space Converter (CSC) 011 : Source from VIP_PARSER A port 100 : Source from VIP_PARSER B port 101 : Source from Transcode (422) 110 : Reserved 111 : Reserved
  [8] VIP2_RGB_OUT_HI_SELECT rw — Video Input Port 2 HI RGB Output Select 0 : Output Type is 420/422 1 : Output Type is RGB
  [7] VIP2_RGB_OUT_LO_SELECT rw — Video Input Port 2 LO RGB Output Select 0 : Output Type is 420/422 1 : Output Type is RGB
  [6] VIP2_RGB_SRC_SELECT rw — Video Input Port 2 RGB Output Path Select 0 : Source from Compositor RGB input 1 : Source from CSC
  [5:3] VIP2_SC_SRC_SELECT rw — Video Input Port 2 SC_M Source Select 000 : Path Disabled 001 : Source from Color Space Converter (CSC) 010 : Source from VIP_PARSER A port 011 : Source from VIP_PARSER B port 100 : Source from Transcode (422) 101 : Reserved 110 : Reserved 111 : Reserved
  [2:0] VIP2_CSC_SRC_SELECT rw — Video Input Port 2 CSC Source Select 000 : Path Disabled 001 : Source from VIP_PARSER A (422) port 010 : Source from VIP_PARSER B port 011 : Source from Transcode (422) 100 : Source from VIP_PARSER A (RGB) port 101 : Source from Compositor (RGB) 110 : Reserved 111 : Reserved
